# PIC32CK2051SG01100 device description
Architecture: CORTEX-M33; Family: PIC32CK; Series: PIC32CKSG01
Registers are 32-bit, read-write, reset 0x0 unless marked. A register's access mark holds for its fields unless they carry their own. Offsets are from the block's base; [hi:lo] are bit positions; {n}, {i} and the like mark numbered series.

## FUSES_USERCFG1 — Defines FUSE parameters
Instances: FUSES_USERCFG1 0x0A000000, FUSES_USERCFG2 0x0A008000
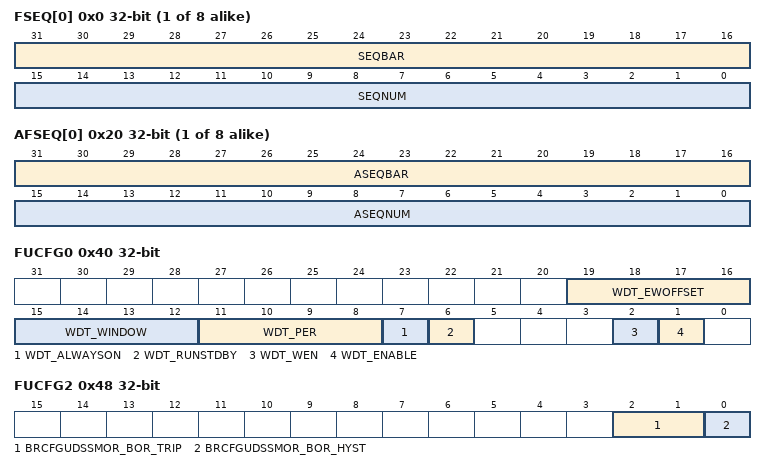
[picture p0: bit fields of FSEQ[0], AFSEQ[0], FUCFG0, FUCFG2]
{0x0+4i} FSEQ[{i}] (i=0..7) reset not defined — Flash Sequence Number
  [31:16] SEQBAR — Sequence Number Bar (Negeated)
  [15:0] SEQNUM — Sequence Number
{0x20+4i} AFSEQ[{i}] (i=0..7) reset not defined — Alternate Flash Sequence Number
  [31:16] ASEQBAR — Alternate Sequence Number Bar (Negeated)
  [15:0] ASEQNUM — Alternate Sequence Number
0x40 FUCFG0 reset not defined — WDT Configuration
  [19:16] WDT_EWOFFSET — Early Warning Interrupt Time Offset
  [15:12] WDT_WINDOW — Window Mode Time-out Period
  [11:8] WDT_PER — Time-out Period
  [7] WDT_ALWAYSON — Always On
  [6] WDT_RUNSTDBY — Run in Standby
  [2] WDT_WEN — Window Mode Enable
  [1] WDT_ENABLE — Enable
0x44 FUCFG1 reset not defined — User Configuration 1 (System Bus Configuration)
0x48 FUCFG2 reset not defined — User Configuration 2 (Deep Sleep SMOR Configuration)
  [2:1] BRCFGUDSSMOR_BOR_TRIP — BOT Trip Points
  [0] BRCFGUDSSMOR_BOR_HYST — BOT Trip Hystersis
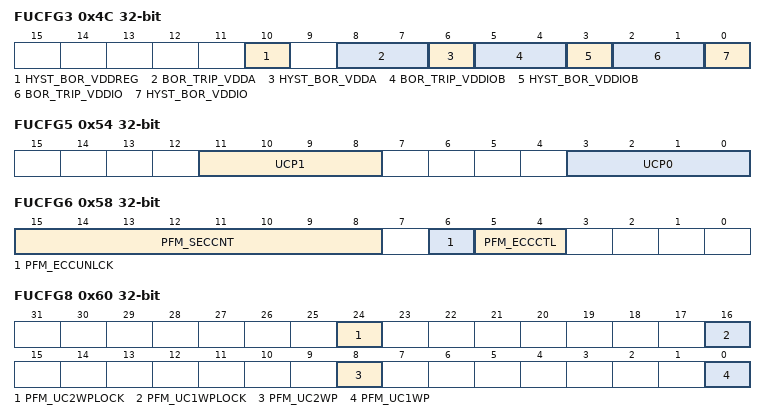
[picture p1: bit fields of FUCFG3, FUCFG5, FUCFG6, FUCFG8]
0x4C FUCFG3 reset not defined — User Configuration 2 (SMOR Configuration)
  [10] HYST_BOR_VDDREG — BOR Trip Point Hystersis for VDDREG
  [8:7] BOR_TRIP_VDDA — BOR Trip Points for VDDANA
  [6] HYST_BOR_VDDA — BOR Trip Point Hystersis for VDDANA
  [5:4] BOR_TRIP_VDDIOB — BOR Trip Points for VDDIOB
  [3] HYST_BOR_VDDIOB — BOR Trip Point Hystersis for VDDIOB
  [2:1] BOR_TRIP_VDDIO — BOR Trip Points for VDDIO
  [0] HYST_BOR_VDDIO — BOR Trip Point Hystersis for VDDIO
0x54 FUCFG5 — User Configuration 5 (VREG Charge Pump Configuration)
  [11:8] UCP1 — User charge pump setting
  [3:0] UCP0 — User charge pump setting
0x58 FUCFG6 reset not defined — User Configuration 6 (FCR ECCCTRL Configuration)
  [15:8] PFM_SECCNT — Flash SEC Count
  [6] PFM_ECCUNLCK — ECC Mode Control Unlock
  [5:4] PFM_ECCCTL — ECC Mode Control
0x5C FUCFG7 reset not defined — User Configuration 7 (FCR CTRLB Configuration)
  [1] PFM_TEMP — NVM Operating Temperature Read Mode
0x60 FUCFG8 reset not defined — User Configuration 8 (FCW CWP Configuration)
  [24] PFM_UC2WPLOCK — User Configuration Page 2 Write Protection Lock
  [16] PFM_UC1WPLOCK — User Configuration Page 1 Write Protection Lock
  [8] PFM_UC2WP — User Configuration Page 2 Write Protect
  [0] PFM_UC1WP — User Configuration Page 1 Write Protect
0x64 FUCFG9 reset not defined — User Configuration 9 (RAM BISR and ECC Configuraiton)
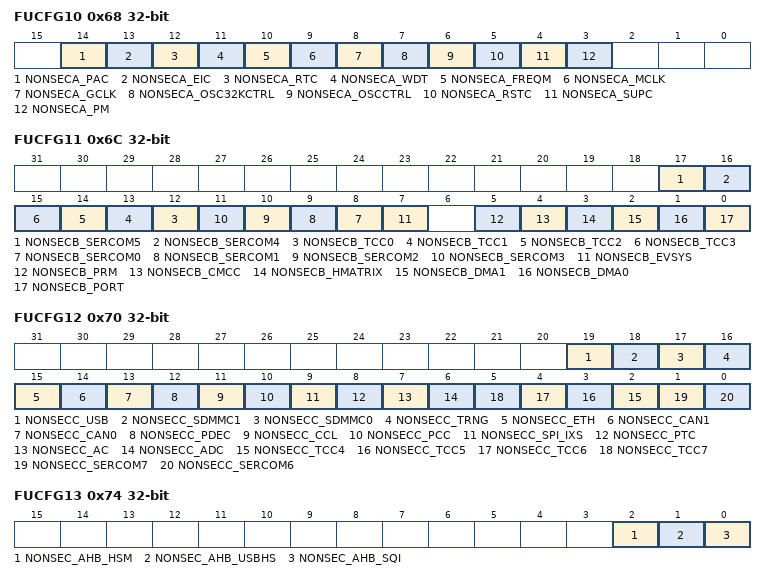
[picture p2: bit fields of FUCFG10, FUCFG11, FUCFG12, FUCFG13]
0x68 FUCFG10 reset not defined — User Configuration 10 (Peripheral Bus A security attribution
  [14] NONSECA_PAC — BOOTROM NONSEC A Peripheral Access Controller secure/non-secure
  [13] NONSECA_EIC — BOOTROM NONSEC A External Interrupt Controller secure/non-secure
  [12] NONSECA_RTC — BOOTROM NONSEC A Real Time Clock secure/non-secure
  [11] NONSECA_WDT — BOOTROM NONSEC A Watchdog Timer secure/non-secure
  [10] NONSECA_FREQM — BOOTROM NONSEC A Frequency Meter secure/non-secure
  [9] NONSECA_MCLK — BOOTROM NONSEC A Main Clock secure/non-secure
  [8] NONSECA_GCLK — BOOTROM NONSEC A Generic Clock secure/non-secure
  [7] NONSECA_OSC32KCTRL — BOOTROM NONSEC A 32k Oscillator Control secure/non-secure
  [6] NONSECA_OSCCTRL — BOOTROM NONSEC A Oscillator Control secure/non-secure
  [5] NONSECA_RSTC — BOOTROM NONSEC A Reset Controller secure/non-secure
  [4] NONSECA_SUPC — BOOTROM NONSEC A Supply Controller secure/non-secure
  [3] NONSECA_PM — BOOTROM NONSEC A Power Manager secure/non-secure
0x6C FUCFG11 reset not defined — User Configuration 11 (Peripheral Bus B security attribution
  [17] NONSECB_SERCOM5 — BOOTROM NONSEC B SERCOM5 secure/non-secure
  [16] NONSECB_SERCOM4 — BOOTROM NONSEC B SERCOM4 secure/non-secure
  [n+12] NONSECB_TCC{n} (n=0..3) — BOOTROM NONSEC B TCC{n} secure/non-secure
  [n+8] NONSECB_SERCOM{n} (n=0..3) — BOOTROM NONSEC B SERCOM{n} secure/non-secure
  [7] NONSECB_EVSYS — BOOTROM NONSEC B Event System secure/non-secure
  [5] NONSECB_PRM — BOOTROM NONSEC B Boot ROM secure/non-secure
  [4] NONSECB_CMCC — BOOTROM NONSEC B Cortex M Cache Controller secure/non-secure
  [3] NONSECB_HMATRIX — BOOTROM NONSEC B HMATRIX secure/non-secure
  [2] NONSECB_DMA1 — BOOTROM NONSEC B DMA1 secure/non-secure
  [1] NONSECB_DMA0 — BOOTROM NONSEC B DMA0 secure/non-secure
  [0] NONSECB_PORT — BOOTROM NONSEC B PORT secure/non-secure
0x70 FUCFG12 reset not defined — User Configuration 12 (Peripheral Bus C security attribution
  [19] NONSECC_USB — BOOTROM NONSEC C Full Speed USB secure/non-secure
  [18] NONSECC_SDMMC1 — BOOTROM NONSEC C SDMMC1 secure/non-secure
  [17] NONSECC_SDMMC0 — BOOTROM NONSEC C SDMMC0 secure/non-secure
  [16] NONSECC_TRNG — BOOTROM NONSEC C TRNG secure/non-secure
  [15] NONSECC_ETH — BOOTROM NONSEC C ETH secure/non-secure
  [14] NONSECC_CAN1 — BOOTROM NONSEC C CAN1 secure/non-secure
  [13] NONSECC_CAN0 — BOOTROM NONSEC C CAN0 secure/non-secure
  [12] NONSECC_PDEC — BOOTROM NONSEC C PDEC secure/non-secure
  [11] NONSECC_CCL — BOOTROM NONSEC C CCL secure/non-secure
  [10] NONSECC_PCC — BOOTROM NONSEC C PCC secure/non-secure
  [9] NONSECC_SPI_IXS — BOOTROM NONSEC C SPI_IXS secure/non-secure
  [8] NONSECC_PTC — BOOTROM NONSEC C PTC secure/non-secure
  [7] NONSECC_AC — BOOTROM NONSEC C Analog Comparator secure/non-secure
  [6] NONSECC_ADC — BOOTROM NONSEC C ADC secure/non-secure
  [n-2] NONSECC_TCC{n} (n=4..7) — BOOTROM NONSEC C TCC{n} secure/non-secure
  [1] NONSECC_SERCOM7 — BOOTROM NONSEC C SERCOM7 secure/non-secure
  [0] NONSECC_SERCOM6 — BOOTROM NONSEC C SERCOM6 secure/non-secure
0x74 FUCFG13 reset not defined — User Configuration 13 (AHB peripheral security attribution
  [2] NONSEC_AHB_HSM — BOOTROM NONSEC AHB HSM secure/non-secure
  [1] NONSEC_AHB_USBHS — BOOTROM NONSEC AHB USB High Speed secure/non-secure
  [0] NONSEC_AHB_SQI — BOOTROM NONSEC AHB SQI secure/non-secure
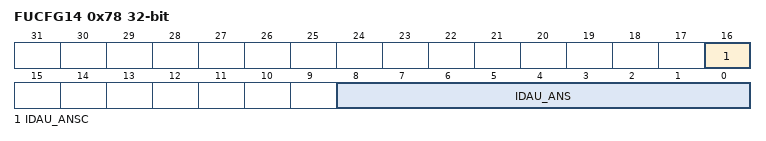
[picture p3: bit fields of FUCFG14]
0x78 FUCFG14 reset not defined — PFM IDAU Configuration
  [16] IDAU_ANSC — Non-secure callable Flash application size
  [8:0] IDAU_ANS — Non-secure Flash application size
0x7C FUCFG15 reset not defined — RAM IDAU Configuration
  [6:0] IDAU_RNS — Non-secure RAM size
0x80 FUCFG16 reset not defined — User Configuration 16 (HSM Firmware Metadata 0 Address)
  [31:0] HSM_PTRMETA0 — HSM Firmware Metadata pointer 0
0xA0 FUCFG24 reset not defined — User Configuration 24 (HSM Firmware Metadata 1 Address)
  [31:0] HSM_PTRMETA1 — HSM Firmware Metadata pointer 1

## Notices in the file
Copyright (c) 2021 Microchip Technology Inc.
SPDX-License-Identifier: Apache-2.0
Licensed under the Apache License, Version 2.0 (the "License");
you may not use this file except in compliance with the License.
You may obtain a copy of the License at
http://www.apache.org/licenses/LICENSE-2.0
Unless required by applicable law or agreed to in writing, software
distributed under the License is distributed on an "AS IS" BASIS,
WITHOUT WARRANTIES OR CONDITIONS OF ANY KIND, either express or implied.
See the License for the specific language governing permissions and
limitations under the License.
